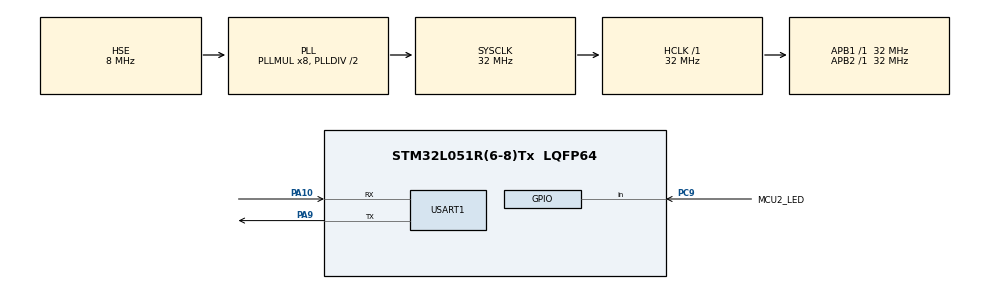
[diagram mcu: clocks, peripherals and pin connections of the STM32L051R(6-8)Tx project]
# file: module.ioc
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IWDG.Prescaler=IWDG_PRESCALER_256
IWDG.Reload=4000
Mcu.Family=STM32L0
Mcu.Name=STM32L051R(6-8)Tx
Mcu.Package=LQFP64
NVIC.RTC_IRQn=true\:0\:0\:false\:false\:true\:true
PA10.Mode=Asynchronous
PA10.Signal=USART1_RX
PA13.Mode=Serial_Wire
PA13.Signal=SYS_SWDIO
PA14.Mode=Serial_Wire
PA14.Signal=SYS_SWCLK
PA9.Mode=Asynchronous
PA9.Signal=USART1_TX
PC14-OSC32_IN.Mode=LSE-External-Oscillator
PC14-OSC32_IN.Signal=RCC_OSC32_IN
PC15-OSC32_OUT.Mode=LSE-External-Oscillator
PC15-OSC32_OUT.Signal=RCC_OSC32_OUT
PC9.GPIO_Label=MCU2_LED
PC9.Signal=GPIO_Input
PH0-OSC_IN.Mode=HSE-External-Oscillator
PH0-OSC_IN.Signal=RCC_OSC_IN
PH1-OSC_OUT.Mode=HSE-External-Oscillator
PH1-OSC_OUT.Signal=RCC_OSC_OUT
ProjectManager.HeapSize=0x200
ProjectManager.StackSize=0x400
ProjectManager.TargetToolchain=EWARM
RCC.AHBFreq_Value=32000000
RCC.APB1Freq_Value=32000000
RCC.APB1TimFreq_Value=32000000
RCC.APB2Freq_Value=32000000
RCC.APB2TimFreq_Value=32000000
RCC.HCLKFreq_Value=32000000
RCC.HSE_VALUE=8000000
RCC.HSI16_VALUE=16000000
RCC.HSI_VALUE=16000000
RCC.MSI_VALUE=2097000
RCC.PLLMUL=RCC_PLLMUL_8
RCC.PLLSourceVirtual=RCC_PLLSOURCE_HSE
RCC.RTCClockSelection=RCC_RTCCLKSOURCE_LSE
RCC.RTCClockSelectionVirtual=RCC_RTCCLKSOURCE_LSE
RCC.SYSCLKFreq_VALUE=32000000
RCC.SYSCLKSource=RCC_SYSCLKSOURCE_PLLCLK
RCC.VCOOutputFreq_Value=64000000
RTC.Alarm-Alarm\ A=RTC_ALARM_A
RTC.AlarmMaskDateWeekDay-Alarm\ A=RTC_ALARMMASK_DATEWEEKDAY
RTC.Minutes_A-Alarm\ A=1
RTC.WakeUpClock-WakeUp=RTC_WAKEUPCLOCK_CK_SPRE_16BITS
RTC.WakeUpCounter-WakeUp=10
USART1.VirtualMode-Asynchronous=VM_ASYNC
USART1.WordLength=WORDLENGTH_8B
VP_IWDG_VS_IWDG.Mode=IWDG_Activate
VP_RTC_VS_RTC_Activate.Mode=RTC_Enabled
VP_RTC_VS_RTC_Alarm_A_Intern.Mode=Alarm A
VP_RTC_VS_RTC_Calendar.Mode=RTC_Calendar
VP_RTC_VS_RTC_WakeUp_intern.Mode=WakeUp
board=module

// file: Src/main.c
/**
  ******************************************************************************
  * File Name          : main.c
  * Description        : Main program body
  ******************************************************************************
  ** This notice applies to any and all portions of this file
  * that are not between comment pairs USER CODE BEGIN and
  * USER CODE END. Other portions of this file, whether
  * inserted by the user or by software development tools
  * are owned by their respective copyright owners.
  *
  * COPYRIGHT(c) 2018 STMicroelectronics
  *
  * Redistribution and use in source and binary forms, with or without modification,
  * are permitted provided that the following conditions are met:
  *   1. Redistributions of source code must retain the above copyright notice,
  *      this list of conditions and the following disclaimer.
  *   2. Redistributions in binary form must reproduce the above copyright notice,
  *      this list of conditions and the following disclaimer in the documentation
  *      and/or other materials provided with the distribution.
  *   3. Neither the name of STMicroelectronics nor the names of its contributors
  *      may be used to endorse or promote products derived from this software
  *      without specific prior written permission.
  *
  * THIS SOFTWARE IS PROVIDED BY THE COPYRIGHT HOLDERS AND CONTRIBUTORS "AS IS"
  * AND ANY EXPRESS OR IMPLIED WARRANTIES, INCLUDING, BUT NOT LIMITED TO, THE
  * IMPLIED WARRANTIES OF MERCHANTABILITY AND FITNESS FOR A PARTICULAR PURPOSE ARE
  * DISCLAIMED. IN NO EVENT SHALL THE COPYRIGHT HOLDER OR CONTRIBUTORS BE LIABLE
  * FOR ANY DIRECT, INDIRECT, INCIDENTAL, SPECIAL, EXEMPLARY, OR CONSEQUENTIAL
  * DAMAGES (INCLUDING, BUT NOT LIMITED TO, PROCUREMENT OF SUBSTITUTE GOODS OR
  * SERVICES; LOSS OF USE, DATA, OR PROFITS; OR BUSINESS INTERRUPTION) HOWEVER
  * CAUSED AND ON ANY THEORY OF LIABILITY, WHETHER IN CONTRACT, STRICT LIABILITY,
  * OR TORT (INCLUDING NEGLIGENCE OR OTHERWISE) ARISING IN ANY WAY OUT OF THE USE
  * OF THIS SOFTWARE, EVEN IF ADVISED OF THE POSSIBILITY OF SUCH DAMAGE.
  *
  ******************************************************************************
  */

#include "main.h"
#include "stm32l0xx_hal.h"
#include "iwdg.h"
#include "rtc.h"
#include "usart.h"
#include "gpio.h"

/* USER CODE BEGIN Includes */
#include "test.h"
#include "system.h"
#include "print_reg.h"
/* USER CODE END Includes */

/* USER CODE BEGIN PV */
/* Private variables ---------------------------------------------------------*/

/* USER CODE END PV */

void SystemClock_Config(void);

/* USER CODE BEGIN PFP */
/* Private function prototypes -----------------------------------------------*/

/* USER CODE END PFP */

int main(void)
{

  /* MCU Configuration----------------------------------------------------------*/

  /* Reset of all peripherals, Initializes the Flash interface and the Systick. */
  HAL_Init();

  /* Configure the system clock */
  SystemClock_Config();

  /* Initialize all configured peripherals */
  MX_GPIO_Init();
  MX_USART1_UART_Init();
  print_iwdg_reg();
//  MX_IWDG_Init();
//  MX_RTC_Init();

  /* USER CODE BEGIN 2 */
    __HAL_RCC_DBGMCU_CLK_ENABLE();
    HAL_DBGMCU_EnableDBGStandbyMode();

	print_sys_boot_reg();

    sys_bootmode();

	if(sys_read_bootmode() == boot_mode_power_on_start)
	{
  		MX_RTC_Init();
  		HAL_UART_Transmit(&huart1, "init RTC.\n", 10, 10);
	}
	else
	{
//        print_rtc_reg();
       	sys_clear_wakeuptimer_flag();
//		print_rtc_reg();
	}
    hrtc.Instance = RTC;

    print_rtc_reg();
//    sys_set_alarm_a_time();
//    print_rtc_reg();

    if(__HAL_RTC_ALARM_GET_FLAG(&hrtc, RTC_FLAG_ALRAF))
    {
		sys_clear_alarm_a_flag();
    	sys_set_alarm_a_time();
    	print_rtc_reg();
        HAL_UART_Transmit(&huart1, "RTC alarm a wakeup.\n", 20,100);
    }

//	test_backupdomain();
  /* USER CODE END 2 */

  /* Infinite loop */
  while (1)
  {

  /* USER CODE BEGIN 3 */
    test_process();

  }
  /* USER CODE END 3 */

}

/** System Clock Configuration
*/
void SystemClock_Config(void)
{

  RCC_OscInitTypeDef RCC_OscInitStruct;
  RCC_ClkInitTypeDef RCC_ClkInitStruct;
  RCC_PeriphCLKInitTypeDef PeriphClkInit;

    /**Configure the main internal regulator output voltage
    */
  __HAL_PWR_VOLTAGESCALING_CONFIG(PWR_REGULATOR_VOLTAGE_SCALE1);

    /**Configure LSE Drive Capability
    */
  __HAL_RCC_LSEDRIVE_CONFIG(RCC_LSEDRIVE_LOW);

    /**Initializes the CPU, AHB and APB busses clocks
    */
  RCC_OscInitStruct.OscillatorType = RCC_OSCILLATORTYPE_LSI|RCC_OSCILLATORTYPE_HSE
                              |RCC_OSCILLATORTYPE_LSE;
  RCC_OscInitStruct.HSEState = RCC_HSE_ON;
  RCC_OscInitStruct.LSEState = RCC_LSE_ON;
  RCC_OscInitStruct.LSIState = RCC_LSI_ON;
  RCC_OscInitStruct.PLL.PLLState = RCC_PLL_ON;
  RCC_OscInitStruct.PLL.PLLSource = RCC_PLLSOURCE_HSE;
  RCC_OscInitStruct.PLL.PLLMUL = RCC_PLLMUL_8;
  RCC_OscInitStruct.PLL.PLLDIV = RCC_PLLDIV_2;
  if (HAL_RCC_OscConfig(&RCC_OscInitStruct) != HAL_OK)
  {
    _Error_Handler(__FILE__, __LINE__);
  }

    /**Initializes the CPU, AHB and APB busses clocks
    */
  RCC_ClkInitStruct.ClockType = RCC_CLOCKTYPE_HCLK|RCC_CLOCKTYPE_SYSCLK
                              |RCC_CLOCKTYPE_PCLK1|RCC_CLOCKTYPE_PCLK2;
  RCC_ClkInitStruct.SYSCLKSource = RCC_SYSCLKSOURCE_PLLCLK;
  RCC_ClkInitStruct.AHBCLKDivider = RCC_SYSCLK_DIV1;
  RCC_ClkInitStruct.APB1CLKDivider = RCC_HCLK_DIV1;
  RCC_ClkInitStruct.APB2CLKDivider = RCC_HCLK_DIV1;

  if (HAL_RCC_ClockConfig(&RCC_ClkInitStruct, FLASH_LATENCY_1) != HAL_OK)
  {
    _Error_Handler(__FILE__, __LINE__);
  }

  PeriphClkInit.PeriphClockSelection = RCC_PERIPHCLK_USART1|RCC_PERIPHCLK_RTC;
  PeriphClkInit.Usart1ClockSelection = RCC_USART1CLKSOURCE_PCLK2;
  PeriphClkInit.RTCClockSelection = RCC_RTCCLKSOURCE_LSE;
  if (HAL_RCCEx_PeriphCLKConfig(&PeriphClkInit) != HAL_OK)
  {
    _Error_Handler(__FILE__, __LINE__);
  }

    /**Configure the Systick interrupt time
    */
  HAL_SYSTICK_Config(HAL_RCC_GetHCLKFreq()/1000);

    /**Configure the Systick
    */
  HAL_SYSTICK_CLKSourceConfig(SYSTICK_CLKSOURCE_HCLK);

  /* SysTick_IRQn interrupt configuration */
  HAL_NVIC_SetPriority(SysTick_IRQn, 0, 0);
}

void _Error_Handler(char * file, int line)
{
  while(1)
  {
  }
}

/************************ (C) COPYRIGHT STMicroelectronics *****END OF FILE****/
